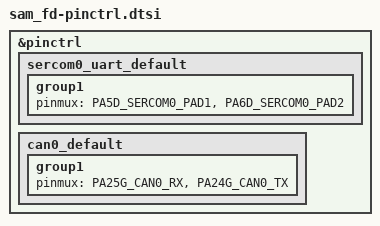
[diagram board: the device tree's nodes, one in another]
/*
 * Copyright (c) 2022 Nordic Semiconductor ASA
 * Copyright (c) 2023 Leon Rinkel
 * SPDX-License-Identifier: Apache-2.0
 */

#include <dt-bindings/pinctrl/samc21e-pinctrl.h>

&pinctrl {
	sercom0_uart_default: sercom0_uart_default {
		group1 {
			pinmux = <PA5D_SERCOM0_PAD1>,
				 <PA6D_SERCOM0_PAD2>;
		};
	};

	can0_default: can0_default {
		group1 {
			pinmux = <PA25G_CAN0_RX>,
				 <PA24G_CAN0_TX>;
		};
	};
};
